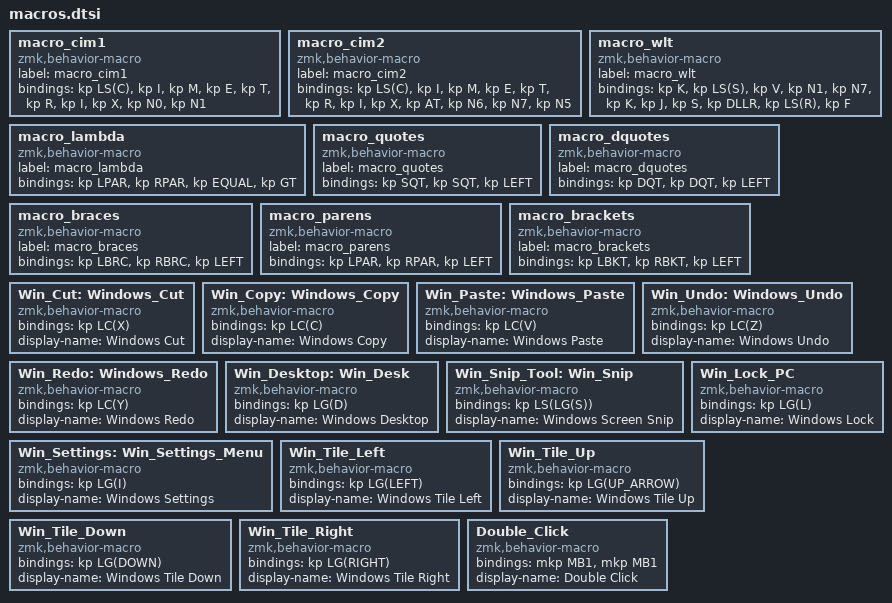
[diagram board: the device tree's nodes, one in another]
  macro_cim1: macro_cim1{
    compatible = "zmk,behavior-macro";
    label = "macro_cim1";
    #binding-cells = <0>;
    bindings = <&kp LS(C)>, <&kp I>, <&kp M>, <&kp E>, <&kp T>, <&kp R>, <&kp I>, <&kp X>, <&kp N0>, <&kp N1>;
  };  
  
  macro_cim2: macro_cim2{
    compatible = "zmk,behavior-macro";
    label = "macro_cim2";
    #binding-cells = <0>;
    bindings = <&kp LS(C)>, <&kp I>, <&kp M>, <&kp E>, <&kp T>, <&kp R>, <&kp I>, <&kp X>, <&kp AT>, <&kp N6>, <&kp N7>, <&kp N5>;
  };
  
  macro_wlt: macro_wlt{
    compatible = "zmk,behavior-macro";
    label = "macro_wlt";
    #binding-cells = <0>;
    bindings = <&kp K>, <&kp LS(S)>, <&kp V>, <&kp N1>, <&kp N7>, <&kp K>, <&kp J>, <&kp S>, <&kp DLLR>, <&kp LS(R)>, <&kp F>;
  };
  
  macro_lambda: macro_lambda{
    compatible = "zmk,behavior-macro";
    label = "macro_lambda";
    #binding-cells = <0>;
    bindings = <&kp LPAR>, <&kp RPAR>, <&kp EQUAL>, <&kp GT>;
  };
  
  macro_quotes: macro_quotes {
    compatible = "zmk,behavior-macro";
    label = "macro_quotes";
    #binding-cells = <0>;
    bindings = <&kp SQT>, <&kp SQT>, <&kp LEFT>;
  };
  
  macro_dquotes: macro_dquotes {
    compatible = "zmk,behavior-macro";
    label = "macro_dquotes";
    #binding-cells = <0>;
    bindings = <&kp DQT>, <&kp DQT>, <&kp LEFT>;
  };
  
  macro_braces: macro_braces {
    compatible = "zmk,behavior-macro";
    label = "macro_braces";
    #binding-cells = <0>;
    bindings = <&kp LBRC>, <&kp RBRC>, <&kp LEFT>;
  };
  
  macro_parens: macro_parens {
    compatible = "zmk,behavior-macro";
    label = "macro_parens";
    #binding-cells = <0>;
    bindings = <&kp LPAR>, <&kp RPAR>, <&kp LEFT>;
  };
  
  macro_brackets: macro_brackets {
    compatible = "zmk,behavior-macro";
    label = "macro_brackets";
    #binding-cells = <0>;
    bindings = <&kp LBKT>, <&kp RBKT>, <&kp LEFT>;
  };

  Win_Cut: Windows_Cut {
    compatible = "zmk,behavior-macro";
    #binding-cells = <0>;
    bindings = <&kp LC(X)>;
    display-name = "Windows Cut";
  };

  Win_Copy: Windows_Copy {
    compatible = "zmk,behavior-macro";
    #binding-cells = <0>;
    bindings = <&kp LC(C)>;
    display-name = "Windows Copy";
  };

  Win_Paste: Windows_Paste {
    compatible = "zmk,behavior-macro";
    #binding-cells = <0>;
    bindings = <&kp LC(V)>;
    display-name = "Windows Paste";
  };

  Win_Undo: Windows_Undo {
    compatible = "zmk,behavior-macro";
    #binding-cells = <0>;
    bindings = <&kp LC(Z)>;
    display-name = "Windows Undo";
  };
  
  Win_Redo: Windows_Redo {
    compatible = "zmk,behavior-macro";
    #binding-cells = <0>;
    bindings = <&kp LC(Y)>;
    display-name = "Windows Redo";
  };

  Win_Desktop: Win_Desk {
    compatible = "zmk,behavior-macro";
    #binding-cells = <0>;
    bindings = <&kp LG(D)>;
    display-name = "Windows Desktop";
  };

  Win_Snip_Tool: Win_Snip {
    compatible = "zmk,behavior-macro";
    #binding-cells = <0>;
    bindings = <&kp LS(LG(S))>;
    display-name = "Windows Screen Snip";
  };

  Win_Settings: Win_Settings_Menu {
    compatible = "zmk,behavior-macro";
    #binding-cells = <0>;
    bindings = <&kp LG(I)>;
    display-name = "Windows Settings";
  };

  Win_Lock_PC: Win_Lock_PC {
    compatible = "zmk,behavior-macro";
    #binding-cells = <0>;
    bindings = <&kp LG(L)>;
    display-name = "Windows Lock";
  };

  Win_Tile_Left: Win_Tile_Left {
    compatible = "zmk,behavior-macro";
    #binding-cells = <0>;
    bindings = <&kp LG(LEFT)>;
    display-name = "Windows Tile Left";
  };

  Win_Tile_Up: Win_Tile_Up {
    compatible = "zmk,behavior-macro";
    #binding-cells = <0>;
    bindings = <&kp LG(UP_ARROW)>;
    display-name = "Windows Tile Up";
  };

  Win_Tile_Down: Win_Tile_Down {
    compatible = "zmk,behavior-macro";
    #binding-cells = <0>;
    bindings = <&kp LG(DOWN)>;
    display-name = "Windows Tile Down";
  };

  Win_Tile_Right: Win_Tile_Right {
    compatible = "zmk,behavior-macro";
    #binding-cells = <0>;
    bindings = <&kp LG(RIGHT)>;
    display-name = "Windows Tile Right";
  };

  Double_Click: Double_Click {
    compatible = "zmk,behavior-macro";
    #binding-cells = <0>;
    bindings = <&mkp MB1 &mkp MB1>;
    display-name = "Double Click";
  };
